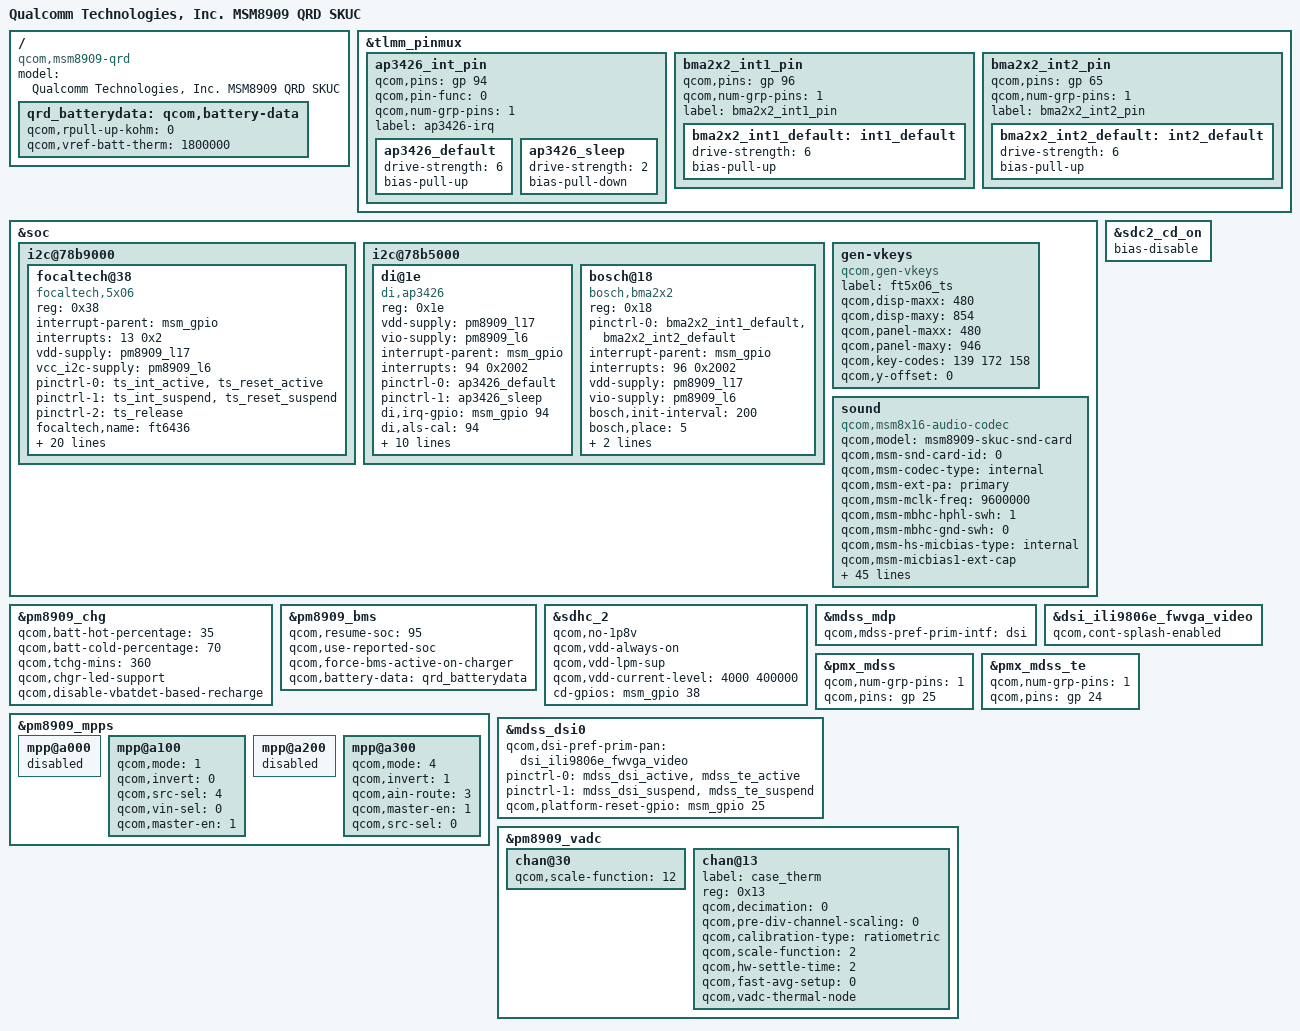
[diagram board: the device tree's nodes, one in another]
/* Copyright (c) 2014-2015, The Linux Foundation. All rights reserved.
 *
 * This program is free software; you can redistribute it and/or modify
 * it under the terms of the GNU General Public License version 2 and
 * only version 2 as published by the Free Software Foundation.
 *
 * This program is distributed in the hope that it will be useful,
 * but WITHOUT ANY WARRANTY; without even the implied warranty of
 * MERCHANTABILITY or FITNESS FOR A PARTICULAR PURPOSE.  See the
 * GNU General Public License for more details.
 */

#include "msm8909-qrd.dtsi"
#include "msm8909-camera-sensor-skuc.dtsi"

/ {
	model = "Qualcomm Technologies, Inc. MSM8909 QRD SKUC";
	compatible = "qcom,msm8909-qrd", "qcom,msm8909", "qcom,qrd";
};

&tlmm_pinmux {
	ap3426_int_pin {
		qcom,pins = <&gp 94>;
		qcom,pin-func = <0>;
		qcom,num-grp-pins = <1>;
		label = "ap3426-irq";
		ap3426_default: ap3426_default {
			drive-strength = <6>;
			bias-pull-up;
		};
		ap3426_sleep: ap3426_sleep {
			drive-strength = <2>;
			bias-pull-down;
		};
	};

	bma2x2_int1_pin {
		qcom,pins = <&gp 96>;
		qcom,num-grp-pins = <1>;
		label = "bma2x2_int1_pin";
		bma2x2_int1_default: int1_default {
			drive-strength = <6>;
			bias-pull-up;
		};
	};

	bma2x2_int2_pin {
		qcom,pins = <&gp 65>;
		qcom,num-grp-pins = <1>;
		label = "bma2x2_int2_pin";
		bma2x2_int2_default: int2_default {
			drive-strength = <6>;
			bias-pull-up;
		};
	};
};

&soc {
	i2c@78b9000 { /* BLSP1 QUP5 */
		focaltech@38 {
			compatible = "focaltech,5x06";
			reg = <0x38>;
			interrupt-parent = <&msm_gpio>;
			interrupts = <13 0x2>;
			vdd-supply = <&pm8909_l17>;
			vcc_i2c-supply = <&pm8909_l6>;
			/* pins used by touchscreen */
			pinctrl-names = "pmx_ts_active","pmx_ts_suspend","pmx_ts_release";
			pinctrl-0 = <&ts_int_active &ts_reset_active>;
			pinctrl-1 = <&ts_int_suspend &ts_reset_suspend>;
			pinctrl-2 = <&ts_release>;
			focaltech,name = "ft6436";
			focaltech,family-id = <0x36>;
			focaltech,reset-gpio = <&msm_gpio 12 0x0>;
			focaltech,irq-gpio = <&msm_gpio 13 0x0>;
			focaltech,display-coords = <0 0 480 854>;
			focaltech,panel-coords = <0 0 480 950>;
			focaltech,no-force-update;
			focaltech,i2c-pull-up;
			focaltech,group-id = <1>;
			focaltech,hard-reset-delay-ms = <20>;
			focaltech,soft-reset-delay-ms = <200>;
			focaltech,num-max-touches = <2>;
			focaltech,fw-delay-aa-ms = <30>;
			focaltech,fw-delay-55-ms = <30>;
			focaltech,fw-upgrade-id1 = <0x79>;
			focaltech,fw-upgrade-id2 = <0x18>;
			focaltech,fw-delay-readid-ms = <10>;
			focaltech,fw-delay-era-flsh-ms = <2000>;
			focaltech,fw-auto-cal;
			focaltech,ignore-id-check;
			focaltech,gesture-support;
		};

	};

	i2c@78b5000 { /* BLSP1 QUP1 */
		di@1e {
			compatible = "di,ap3426";
			reg = <0x1e>;
			vdd-supply = <&pm8909_l17>;
			vio-supply = <&pm8909_l6>;
			interrupt-parent = <&msm_gpio>;
			interrupts = <94 0x2002>;
			pinctrl-names = "default","sleep";
			pinctrl-0 = <&ap3426_default>;
			pinctrl-1 = <&ap3426_sleep>;
			di,irq-gpio = <&msm_gpio 94 0x2002>;
			di,als-cal = <94>;
			di,als-gain = <0>;
			di,als-persist = <1>;
			di,ps-gain = <1>;
			di,ps-persist = <2>;
			di,ps-led-driver = <3>;
			di,ps-mean-time = <0>;
			di,ps-integrated-time = <0>;
			di,ps-distance-table = <887 282 111 78 53 46>;
			di,als-sensitivity = <50>;
			di,wakeup-threshold = <4>;
		};

		bosch@18 { /* Accelerometer sensor */
			compatible = "bosch,bma2x2";
			reg = <0x18>;
			pinctrl-names = "default";
			pinctrl-0 = <&bma2x2_int1_default &bma2x2_int2_default>;
			interrupt-parent = <&msm_gpio>;
			interrupts = <96 0x2002>;
			vdd-supply = <&pm8909_l17>;
			vio-supply = <&pm8909_l6>;
			bosch,init-interval = <200>;
			bosch,place = <5>;
			bosch,gpio-int1 = <&msm_gpio 96 0x2002>;
			bosch,gpio-int2 = <&msm_gpio 65 0x2002>;
		};
	};

	gen-vkeys {
		compatible = "qcom,gen-vkeys";
		label = "ft5x06_ts";
		qcom,disp-maxx = <480>;
		qcom,disp-maxy = <854>;
		qcom,panel-maxx = <480>;
		qcom,panel-maxy = <946>;
		qcom,key-codes = <139 172 158>;
		qcom,y-offset = <0>;
	};

	sound {
		compatible = "qcom,msm8x16-audio-codec";
		qcom,model = "msm8909-skuc-snd-card";
		qcom,msm-snd-card-id = <0>;
		qcom,msm-codec-type = "internal";
		qcom,msm-ext-pa = "primary";
		qcom,msm-mclk-freq = <9600000>;
		qcom,msm-mbhc-hphl-swh = <1>;
		qcom,msm-mbhc-gnd-swh = <0>;
		qcom,msm-hs-micbias-type = "internal";
		qcom,msm-micbias1-ext-cap;
		qcom,msm-micbias2-ext-cap;
		qcom,audio-routing =
			"RX_BIAS", "MCLK",
			"SPK_RX_BIAS", "MCLK",
			"INT_LDO_H", "MCLK",
			"MIC BIAS Internal1", "Handset Mic",
			"MIC BIAS Internal2", "Headset Mic",
			"MIC BIAS Internal3", "Secondary Mic",
			"AMIC1", "MIC BIAS Internal1",
			"AMIC2", "MIC BIAS Internal2",
			"AMIC3", "MIC BIAS Internal3";
		pinctrl-names = "cdc_lines_act",
				"cdc_lines_sus";
		pinctrl-0 = <&cdc_pdm_lines_act>;
		pinctrl-1 = <&cdc_pdm_lines_sus>;
		asoc-platform = <&pcm0>, <&pcm1>, <&voip>, <&voice>,
				<&loopback>, <&compress>, <&hostless>,
				<&afe>, <&lsm>, <&routing>, <&lpa>,
				<&voice_svc>;
		asoc-platform-names = "msm-pcm-dsp.0", "msm-pcm-dsp.1",
				"msm-voip-dsp", "msm-pcm-voice", "msm-pcm-loopback",
				"msm-compress-dsp", "msm-pcm-hostless", "msm-pcm-afe",
				"msm-lsm-client", "msm-pcm-routing", "msm-pcm-lpa",
				"msm-voice-svc";
		asoc-cpu = <&dai_pri_auxpcm>, <&dai_hdmi>,
				<&dai_mi2s0>, <&dai_mi2s1>, <&dai_mi2s2>, <&dai_mi2s3>,
				<&sb_0_rx>, <&sb_0_tx>, <&sb_1_rx>, <&sb_1_tx>,
				<&sb_3_rx>, <&sb_3_tx>, <&sb_4_rx>, <&sb_4_tx>,
				<&bt_sco_rx>, <&bt_sco_tx>, <&int_fm_rx>, <&int_fm_tx>,
				<&afe_pcm_rx>, <&afe_pcm_tx>, <&afe_proxy_rx>, <&afe_proxy_tx>,
				<&incall_record_rx>, <&incall_record_tx>, <&incall_music_rx>,
				<&incall_music_2_rx>;
		asoc-cpu-names = "msm-dai-q6-auxpcm.1", "msm-dai-q6-hdmi.8",
				"msm-dai-q6-mi2s.0", "msm-dai-q6-mi2s.1",
				"msm-dai-q6-mi2s.2", "msm-dai-q6-mi2s.3",
				"msm-dai-q6-dev.16384", "msm-dai-q6-dev.16385",
				"msm-dai-q6-dev.16386", "msm-dai-q6-dev.16387",
				"msm-dai-q6-dev.16390", "msm-dai-q6-dev.16391",
				"msm-dai-q6-dev.16392", "msm-dai-q6-dev.16393",
				"msm-dai-q6-dev.12288", "msm-dai-q6-dev.12289",
				"msm-dai-q6-dev.12292", "msm-dai-q6-dev.12293",
				"msm-dai-q6-dev.224", "msm-dai-q6-dev.225",
				"msm-dai-q6-dev.241", "msm-dai-q6-dev.240",
				"msm-dai-q6-dev.32771", "msm-dai-q6-dev.32772",
				"msm-dai-q6-dev.32773", "msm-dai-q6-dev.32770";
		asoc-codec = <&stub_codec>, <&pm8909_conga_dig>;
		asoc-codec-names = "msm-stub-codec.1", "tombak_codec";
	};
};

&pm8909_chg {
	qcom,batt-hot-percentage = <35>;
	qcom,batt-cold-percentage = <70>;
	qcom,tchg-mins = <360>;
	qcom,chgr-led-support;
	qcom,disable-vbatdet-based-recharge;
	status = "okay";
};

/ {
	qrd_batterydata: qcom,battery-data {
		qcom,rpull-up-kohm = <0>;
		qcom,vref-batt-therm = <1800000>;

		#include "batterydata-qrd-skuc-4v2-2000mah.dtsi"
	};
};

&pm8909_bms {
	status = "okay";
	qcom,resume-soc = <95>;
	qcom,use-reported-soc;
	qcom,force-bms-active-on-charger;
	qcom,battery-data = <&qrd_batterydata>;
};

&sdc2_cd_on {
	/delete-property/  bias-pull-up;
	bias-disable;
};

&sdhc_2 {
	qcom,no-1p8v;
	qcom,vdd-always-on;
	qcom,vdd-lpm-sup;

	qcom,vdd-current-level = <4000 400000>;

	cd-gpios = <&msm_gpio 38 0x0>;
};

&pm8909_mpps {
	mpp@a000 { /* MPP 1 */
		/* VDD_PX */
		status = "disabled";
	};

	mpp@a100 { /* MPP 2 */
		/* Backlight PWM */
		qcom,mode = <1>;		/* Digital output */
		qcom,invert = <0>;		/* Disable invert */
		qcom,src-sel = <4>;		/* DTEST1 */
		qcom,vin-sel = <0>;		/* VPH_PWR */
		qcom,master-en = <1>;		/* Enable MPP */
	};

	mpp@a200 { /* MPP 3 */
		/* VREF DAC */
		status = "disabled";
	};

	mpp@a300 { /* MPP 4 */
		 /* PA_THERM config */
		 qcom,mode = <4>; /* AIN input */
		 qcom,invert = <1>; /* Enable MPP */
		 qcom,ain-route = <3>; /* AMUX 8 */
		 qcom,master-en = <1>;
		 qcom,src-sel = <0>; /* Function constant */
	};
};

#include "dsi-panel-ili9806e-fwvga-video.dtsi"

&mdss_mdp {
	qcom,mdss-pref-prim-intf = "dsi";
};

&dsi_ili9806e_fwvga_video {
	qcom,cont-splash-enabled;
};

&pmx_mdss {
	qcom,num-grp-pins = <1>;
	qcom,pins = <&gp 25>;
};

&pmx_mdss_te {
	qcom,num-grp-pins = <1>;
	qcom,pins = <&gp 24>;
};

&mdss_dsi0 {
	qcom,dsi-pref-prim-pan = <&dsi_ili9806e_fwvga_video>;
	pinctrl-names = "mdss_default", "mdss_sleep";
	pinctrl-0 = <&mdss_dsi_active &mdss_te_active>;
	pinctrl-1 = <&mdss_dsi_suspend &mdss_te_suspend>;

	qcom,platform-reset-gpio = <&msm_gpio 25 0>;
};

&pm8909_vadc {
	chan@30 {
		qcom,scale-function = <12>;
	};

	chan@13 {
		label = "case_therm";
		reg = <0x13>;
		qcom,decimation = <0>;
		qcom,pre-div-channel-scaling = <0>;
		qcom,calibration-type = "ratiometric";
		qcom,scale-function = <2>;
		qcom,hw-settle-time = <2>;
		qcom,fast-avg-setup = <0>;
		qcom,vadc-thermal-node;
	};
};
